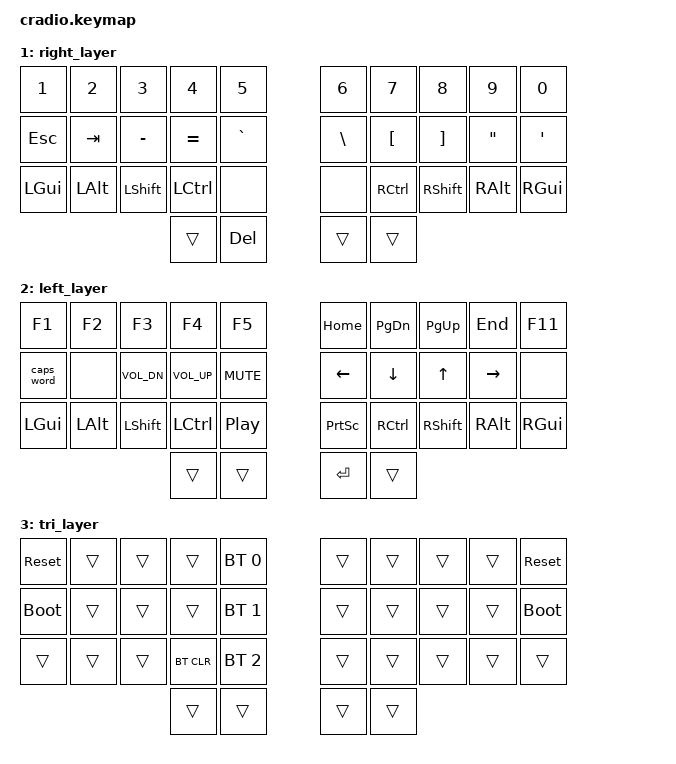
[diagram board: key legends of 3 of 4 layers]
// Copyright (c) 2022 The ZMK Contributors
// SPDX-License-Identifier: MIT

#include <behaviors.dtsi>
#include <dt-bindings/zmk/keys.h>
#include <dt-bindings/zmk/bt.h>

// Home row mods macro
#define HRML(k1,k2,k3,k4) &ht LGUI k1  &ht LALT k2  &ht LSHFT k3  &ht LCTRL k4
#define HRMR(k1,k2,k3,k4) &ht RCTRL k1  &ht RSHFT k2  &ht RALT k3  &ht RGUI k4

/ {
    behaviors {
        ht: hold_tap {
            compatible = "zmk,behavior-hold-tap";
            #binding-cells = <2>;
            flavor = "tap-preferred";
            tapping-term-ms = <220>;
            quick-tap-ms = <150>;
            require-prior-idle-ms = <100>;
            bindings = <&kp>, <&kp>;
        };
    };

    conditional_layers {
        compatible = "zmk,conditional-layers";
        tri_layer {
            if-layers = <1 2>;
            then-layer = <3>;
        };
    };

    keymap {
        compatible = "zmk,keymap";
        default_layer {
            bindings = <
        //╭──────────┬──────────┬──────────┬──────────┬──────────╮   ╭──────────┬──────────┬──────────┬──────────┬──────────╮
            &kp Q      &kp W      &kp E      &kp R      &kp T          &kp Y      &kp U      &kp I      &kp O      &kp P
        //├──────────┼──────────┼──────────┼──────────┼──────────┤   ├──────────┼──────────┼──────────┼──────────┼──────────┤
            &kp A      &kp S      &kp D      &kp F      &kp G          &kp H      &kp J      &kp K      &kp L      &kp SEMI
        //├──────────┼──────────┼──────────┼──────────┼──────────┤   ├──────────┼──────────┼──────────┼──────────┼──────────┤
            HRML(Z,      X,          C,         V)      &kp B          &kp N      HRMR(M,      COMMA,     DOT,       FSLH)
        //╰──────────┴──────────┴──────────┼──────────┼──────────┤   ├──────────┼──────────┼──────────┴──────────┴──────────╯
                                              &mo 2    &kp SPACE       &kp BSPC     &mo 1
        //                                 ╰──────────┴──────────╯   ╰──────────┴──────────╯
            >;
        };

        right_layer {
            bindings = <
        //╭──────────┬──────────┬──────────┬──────────┬──────────╮   ╭──────────┬──────────┬──────────┬──────────┬──────────╮
        //│    1     │    2     │    3     │    4     │    5     │   │    6     │    7     │    8     │    9     │    0     │
             &kp N1     &kp N2     &kp N3     &kp N4     &kp N5         &kp N6     &kp N7     &kp N8     &kp N9    &kp N0
        //├──────────┼──────────┼──────────┼──────────┼──────────┤   ├──────────┼──────────┼──────────┼──────────┼──────────┤
        //│          │          │    - _   │    = +   │    ` ~   │   │   \ |    │   [ {    │   ] }    │    "     │    '     │
            &kp ESC    &kp TAB   &kp MINUS   &kp EQUAL  &kp GRAVE      &kp BSLH   &kp LBKT   &kp RBKT    &kp DQT   &kp SQT
        //├──────────┼──────────┼──────────┼──────────┼──────────┤   ├──────────┼──────────┼──────────┼──────────┼──────────┤
            &kp LGUI   &kp LALT   &kp LSHFT  &kp LCTRL  &none          &none      &kp RCTRL  &kp RSHFT  &kp RALT   &kp RGUI
        //╰──────────┴──────────┴──────────┼──────────┼──────────┤   ├──────────┼──────────┼──────────┴──────────┴──────────╯
                                             &trans     &kp DEL        &trans     &trans
        //                                 ╰──────────┴──────────╯   ╰──────────┴──────────╯
            >;
        };

        left_layer {
            bindings = <
        //╭──────────┬──────────┬──────────┬──────────┬──────────╮   ╭──────────┬──────────┬──────────┬──────────┬──────────╮
             &kp F1     &kp F2     &kp F3     &kp F4     &kp F5        &kp HOME  &kp PG_DN  &kp PG_UP   &kp END    &kp F11
        //├──────────┼──────────┼──────────┼──────────┼──────────┤   ├──────────┼──────────┼──────────┼──────────┼──────────┤
           &caps_word  &none  &kp C_VOL_DN &kp C_VOL_UP &kp C_MUTE    &kp LEFT   &kp DOWN    &kp UP    &kp RIGHT    &none
        //├──────────┼──────────┼──────────┼──────────┼──────────┤   ├──────────┼──────────┼──────────┼──────────┼──────────┤
            &kp LGUI   &kp LALT   &kp LSHFT  &kp LCTRL  &kp C_PP       &kp PSCRN  &kp RCTRL  &kp RSHFT  &kp RALT   &kp RGUI
        //╰──────────┴──────────┴──────────┼──────────┼──────────┤   ├──────────┼──────────┼──────────┴──────────┴──────────╯
                                             &trans     &trans         &kp ENTER   &trans
        //                                 ╰──────────┴──────────╯   ╰──────────┴──────────╯
            >;
        };

        tri_layer {
            bindings = <
        //╭──────────┬──────────┬──────────┬──────────┬──────────╮   ╭──────────┬──────────┬──────────┬──────────┬──────────╮
        //│ RESET    │          │          │          │PROFILE 0 │   │          │          │          │          │  RESET   │
           &sys_reset  &trans     &trans     &trans    &bt BT_SEL 0    &trans     &trans     &trans     &trans    &sys_reset
        //├──────────┼──────────┼──────────┼──────────┼──────────┤   ├──────────┼──────────┼──────────┼──────────┼──────────┤
        //│BOOTLOADER│          │          │          │PROFILE 1 │   │          │          │          │          │BOOTLOADER│
          &bootloader  &trans     &trans     &trans    &bt BT_SEL 1    &trans     &trans     &trans     &trans    &bootloader
        //├──────────┼──────────┼──────────┼──────────┼──────────┤   ├──────────┼──────────┼──────────┼──────────┼──────────┤
        //│          │          │          │ CLEAR BT │PROFILE 2 │   │          │          │          │          │          │
            &trans     &trans     &trans    &bt BT_CLR &bt BT_SEL 2    &trans     &trans     &trans     &trans     &trans
        //╰──────────┴──────────┴──────────┼──────────┼──────────┤   ├──────────┼──────────┼──────────┴──────────┴──────────╯
                                             &trans     &trans         &trans     &trans
        //                                 ╰──────────┴──────────╯   ╰──────────┴──────────╯
            >;
        };
    };
};
